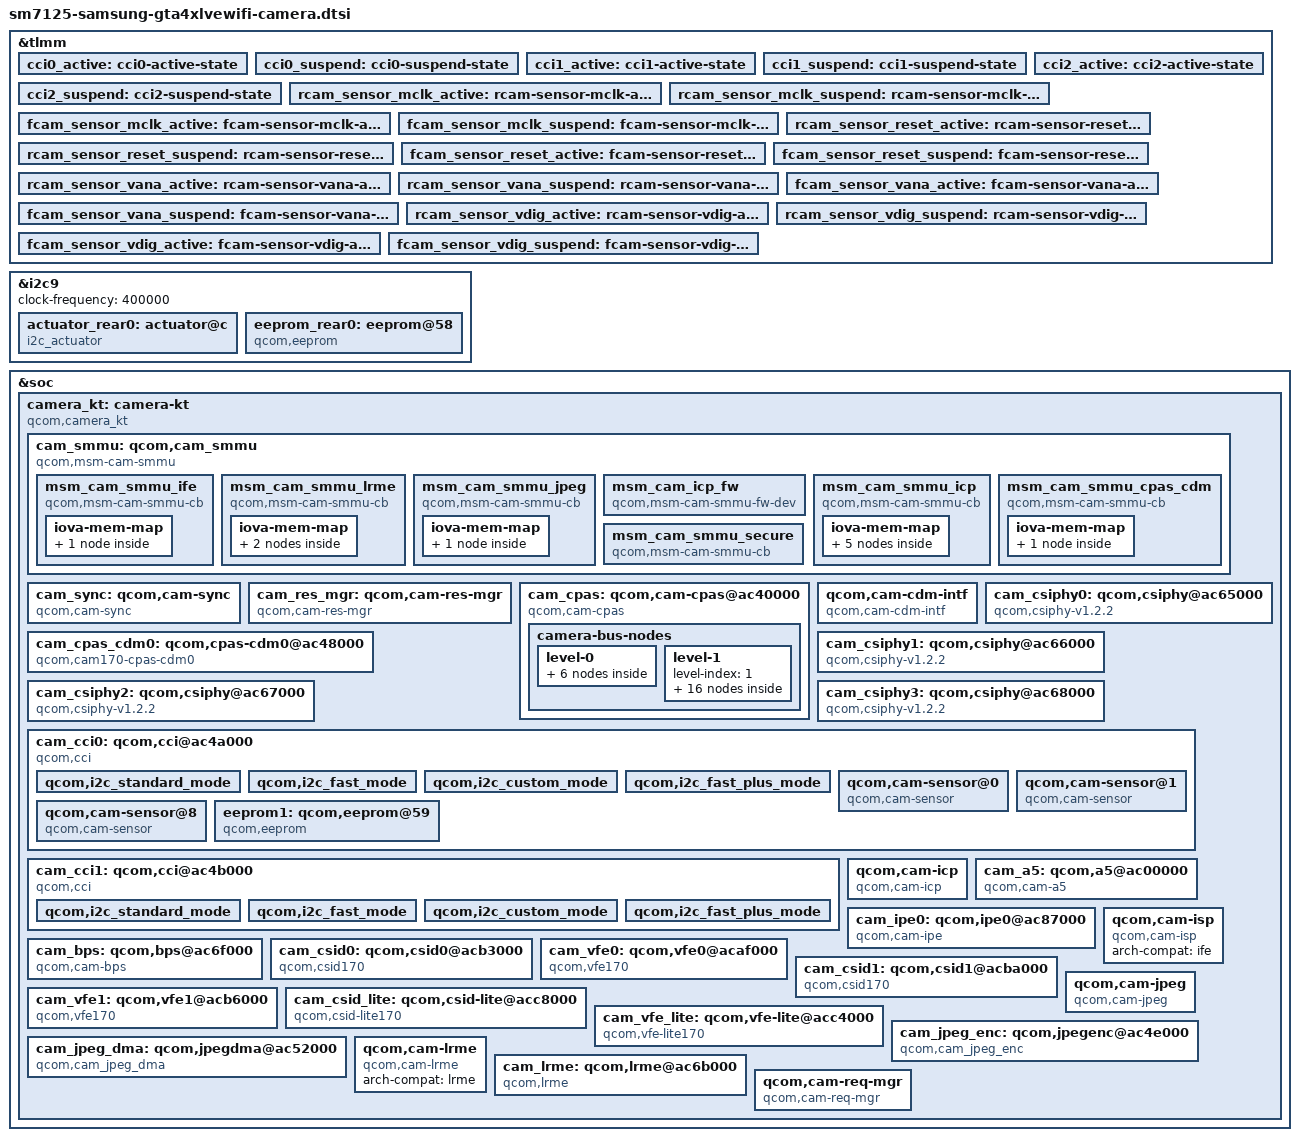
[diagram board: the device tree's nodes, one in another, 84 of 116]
// SPDX-License-Identifier: GPL-2.0
/*
 * Qualcomm Spectra CamX (camera_kt) Device Tree for
 * Samsung Galaxy Tab S6 Lite (2022) Wi-Fi (SM-P613 / gta4xlvewifi, SM7125 / atoll).
 *
 * Sensors:
 *   - Rear  (slot 0): Samsung S5K4HA (8MP, CCI0 Master 0, 0x5A, CSIPHY0)
 *                     + AF actuator (i2c9 @ 0x0C) + EEPROM (i2c9 @ 0x58)
 *   - Front (slot 1 & 8): GalaxyCore GC5035 (5MP, CCI0 Master 1, 0x6E, CSIPHY2)
 *                     + OTP EEPROM (CCI0 Master 1 @ 0x59)
 */

#include <dt-bindings/camera/msm-camera.h>
#include <dt-bindings/clock/qcom,camcc-sc7180.h>
#include <dt-bindings/clock/qcom,gcc-sc7180.h>
#include <dt-bindings/interconnect/qcom,sc7180.h>
#include <dt-bindings/interrupt-controller/arm-gic.h>

&tlmm {
	cci0_active: cci0-active-state {
		pins = "gpio17", "gpio18";
		function = "cci_i2c";
		drive-strength = <2>;
		bias-pull-up;
	};

	cci0_suspend: cci0-suspend-state {
		pins = "gpio17", "gpio18";
		function = "gpio";
		drive-strength = <2>;
		bias-pull-down;
	};

	cci1_active: cci1-active-state {
		pins = "gpio19", "gpio20";
		function = "cci_i2c";
		drive-strength = <2>;
		bias-pull-up;
	};

	cci1_suspend: cci1-suspend-state {
		pins = "gpio19", "gpio20";
		function = "gpio";
		drive-strength = <2>;
		bias-pull-down;
	};

	cci2_active: cci2-active-state {
		pins = "gpio27", "gpio28";
		function = "cci_i2c";
		drive-strength = <2>;
		bias-pull-up;
	};

	cci2_suspend: cci2-suspend-state {
		pins = "gpio27", "gpio28";
		function = "gpio";
		drive-strength = <2>;
		bias-pull-down;
	};

	rcam_sensor_mclk_active: rcam-sensor-mclk-active-state {
		pins = "gpio13";
		function = "cam_mclk";
		drive-strength = <4>;
		bias-disable;
	};

	rcam_sensor_mclk_suspend: rcam-sensor-mclk-suspend-state {
		pins = "gpio13";
		function = "cam_mclk";
		drive-strength = <4>;
		bias-pull-down;
		output-low;
	};

	fcam_sensor_mclk_active: fcam-sensor-mclk-active-state {
		pins = "gpio23";
		function = "cam_mclk";
		drive-strength = <4>;
		bias-disable;
	};

	fcam_sensor_mclk_suspend: fcam-sensor-mclk-suspend-state {
		pins = "gpio23";
		function = "cam_mclk";
		drive-strength = <4>;
		bias-pull-down;
		output-low;
	};

	rcam_sensor_reset_active: rcam-sensor-reset-active-state {
		pins = "gpio24";
		function = "gpio";
		drive-strength = <2>;
		bias-disable;
	};

	rcam_sensor_reset_suspend: rcam-sensor-reset-suspend-state {
		pins = "gpio24";
		function = "gpio";
		drive-strength = <2>;
		bias-pull-down;
	};

	fcam_sensor_reset_active: fcam-sensor-reset-active-state {
		pins = "gpio21";
		function = "gpio";
		drive-strength = <2>;
		bias-disable;
	};

	fcam_sensor_reset_suspend: fcam-sensor-reset-suspend-state {
		pins = "gpio21";
		function = "gpio";
		drive-strength = <2>;
		bias-pull-down;
	};

	rcam_sensor_vana_active: rcam-sensor-vana-active-state {
		pins = "gpio22";
		function = "gpio";
		drive-strength = <2>;
		bias-disable;
	};

	rcam_sensor_vana_suspend: rcam-sensor-vana-suspend-state {
		pins = "gpio22";
		function = "gpio";
		drive-strength = <2>;
		bias-pull-down;
	};

	fcam_sensor_vana_active: fcam-sensor-vana-active-state {
		pins = "gpio63";
		function = "gpio";
		drive-strength = <2>;
		bias-disable;
	};

	fcam_sensor_vana_suspend: fcam-sensor-vana-suspend-state {
		pins = "gpio63";
		function = "gpio";
		drive-strength = <2>;
		bias-pull-down;
	};

	rcam_sensor_vdig_active: rcam-sensor-vdig-active-state {
		pins = "gpio10";
		function = "gpio";
		drive-strength = <2>;
		bias-disable;
	};

	rcam_sensor_vdig_suspend: rcam-sensor-vdig-suspend-state {
		pins = "gpio10";
		function = "gpio";
		drive-strength = <2>;
		bias-pull-down;
	};

	fcam_sensor_vdig_active: fcam-sensor-vdig-active-state {
		pins = "gpio14";
		function = "gpio";
		drive-strength = <2>;
		bias-disable;
	};

	fcam_sensor_vdig_suspend: fcam-sensor-vdig-suspend-state {
		pins = "gpio14";
		function = "gpio";
		drive-strength = <2>;
		bias-pull-down;
	};
};

&i2c9 {
	clock-frequency = <400000>;
	status = "okay";

	actuator_rear0: actuator@c {
		cell-index = <0>;
		reg = <0x0c>;
		slave-addr = <0x18>;
		compatible = "i2c_actuator";

		rgltr-cntrl-support;
		cam_vaf-supply = <&vreg_l5a_2p7>;
		regulator-names = "cam_vaf";
		rgltr-min-voltage = <2800000>;
		rgltr-max-voltage = <2800000>;
		rgltr-load-current = <200000>;
	};

	eeprom_rear0: eeprom@58 {
		cell-index = <0>;
		reg = <0x58>;
		slave-addr = <0xb0>;
		compatible = "qcom,eeprom";
		i2c-freq-mode = <1>;
		sub-type = <2>;

		cam_vio-supply = <&vreg_l18a_3p0>;
		cam_vaf-supply = <&vreg_l5a_2p7>;
		regulator-names = "cam_vio", "cam_vaf", "cam_vana", "cam_vdig";
		rgltr-cntrl-support;
		rgltr-min-voltage = <1800000 2800000 0 0>;
		rgltr-max-voltage = <1800000 2800000 0 0>;
		rgltr-load-current = <200000 200000 0 0>;
		power-domains = <&camcc TITAN_TOP_GDSC>;

		gpio-no-mux = <0>;
		pinctrl-names = "cam_default", "cam_suspend";
		pinctrl-0 = <&rcam_sensor_mclk_active &rcam_sensor_reset_active
			     &rcam_sensor_vana_active &rcam_sensor_vdig_active>;
		pinctrl-1 = <&rcam_sensor_mclk_suspend &rcam_sensor_reset_suspend
			     &rcam_sensor_vana_suspend &rcam_sensor_vdig_suspend>;
		gpios = <&tlmm 13 0>,
			<&tlmm 24 0>,
			<&tlmm 22 0>,
			<&tlmm 10 0>;
		gpio-reset = <1>;
		gpio-vana = <2>;
		gpio-vdig = <3>;
		gpio-req-tbl-num = <0 1 2 3>;
		gpio-req-tbl-flags = <1 0 0 0>;
		gpio-req-tbl-label = "CAMIF_MCLK0", "CAM_RESET0",
				     "CAM_VANA", "CAM_VDIG";
	};
};

&soc {
	camera_kt: camera-kt {
		compatible = "qcom,camera_kt";
		#address-cells = <1>;
		#size-cells = <1>;
		ranges = <0 0 0 0xffffffff>;
		status = "okay";

		cam_smmu: qcom,cam_smmu {
			compatible = "qcom,msm-cam-smmu", "simple-bus";
			status = "okay";

			msm_cam_smmu_ife {
				compatible = "qcom,msm-cam-smmu-cb";
				iommus = <&apps_smmu 0x820 0x0>,
					 <&apps_smmu 0x840 0x0>,
					 <&apps_smmu 0x860 0x0>;
				cam-smmu-label = "ife";
				iova-mem-map {
					iova-mem-region-io {
						iova-region-name = "io";
						iova-region-start = <0x7400000>;
						iova-region-len = <0xd8c00000>;
						iova-region-id = <0x3>;
						status = "okay";
					};
				};
			};

			msm_cam_smmu_lrme {
				compatible = "qcom,msm-cam-smmu-cb";
				iommus = <&apps_smmu 0x0cc0 0x0>,
					 <&apps_smmu 0x0d40 0x0>;
				cam-smmu-label = "lrme";
				iova-mem-map {
					iova-mem-region-shared {
						iova-region-name = "shared";
						iova-region-start = <0x7400000>;
						iova-region-len = <0x6400000>;
						iova-region-id = <0x1>;
						status = "okay";
					};
					iova-mem-region-io {
						iova-region-name = "io";
						iova-region-start = <0xd800000>;
						iova-region-len = <0xd2800000>;
						iova-region-id = <0x3>;
						status = "okay";
					};
				};
			};

			msm_cam_smmu_jpeg {
				compatible = "qcom,msm-cam-smmu-cb";
				iommus = <&apps_smmu 0xd80 0x20>,
					 <&apps_smmu 0xda0 0x20>;
				cam-smmu-label = "jpeg";
				iova-mem-map {
					iova-mem-region-io {
						iova-region-name = "io";
						iova-region-start = <0x7400000>;
						iova-region-len = <0xd8c00000>;
						iova-region-id = <0x3>;
						status = "okay";
					};
				};
			};

			msm_cam_icp_fw {
				compatible = "qcom,msm-cam-smmu-fw-dev";
				cam-smmu-label = "icp";
				memory-region = <&camera_region>;
			};

			msm_cam_smmu_icp {
				compatible = "qcom,msm-cam-smmu-cb";
				iommus = <&apps_smmu 0x0ce2 0x0>,
					 <&apps_smmu 0x0c80 0x0>,
					 <&apps_smmu 0x0ca0 0x0>,
					 <&apps_smmu 0x0d00 0x0>,
					 <&apps_smmu 0x0d20 0x0>;
				cam-smmu-label = "icp";
				iova-mem-map {
					iova-mem-region-firmware {
						iova-region-name = "firmware";
						iova-region-start = <0x0>;
						iova-region-len = <0x500000>;
						iova-region-id = <0x0>;
						status = "okay";
					};

					iova-mem-region-shared {
						iova-region-name = "shared";
						iova-region-start = <0x7400000>;
						iova-region-len = <0x9600000>;
						iova-region-id = <0x1>;
						status = "okay";
					};

					iova-mem-region-secondary-heap {
						iova-region-name = "secheap";
						iova-region-start = <0x10a00000>;
						iova-region-len = <0x100000>;
						iova-region-id = <0x4>;
						status = "okay";
					};

					iova-mem-region-io {
						iova-region-name = "io";
						iova-region-start = <0x10c00000>;
						iova-region-len = <0xcf300000>;
						iova-region-id = <0x3>;
						status = "okay";
					};

					iova-mem-qdss-region {
						iova-region-name = "qdss";
						iova-region-start = <0x10b00000>;
						iova-region-len = <0x100000>;
						iova-region-id = <0x5>;
						qdss-phy-addr = <0x16790000>;
						status = "okay";
					};
				};
			};

			msm_cam_smmu_cpas_cdm {
				compatible = "qcom,msm-cam-smmu-cb";
				iommus = <&apps_smmu 0x0d60 0x0>,
					 <&apps_smmu 0x0d61 0x0>;
				cam-smmu-label = "cpas-cdm";
				iova-mem-map {
					iova-mem-region-io {
						iova-region-name = "io";
						iova-region-start = <0x7400000>;
						iova-region-len = <0xd8c00000>;
						iova-region-id = <0x3>;
						status = "okay";
					};
				};
			};

			msm_cam_smmu_secure {
				compatible = "qcom,msm-cam-smmu-cb";
				cam-smmu-label = "cam-secure";
				qcom,secure-cb;
			};
		};

		cam_sync: qcom,cam-sync {
			compatible = "qcom,cam-sync";
			status = "okay";
		};

		cam_res_mgr: qcom,cam-res-mgr {
			compatible = "qcom,cam-res-mgr";
			status = "okay";
		};

		cam_cpas: qcom,cam-cpas@ac40000 {
			cell-index = <0>;
			compatible = "qcom,cam-cpas";
			label = "cpas";
			arch-compat = "cpas_top";
			status = "okay";
			reg-names = "cam_cpas_top", "cam_camnoc";
			reg = <0x0ac40000 0x1000>,
			      <0x0ac42000 0x5000>;
			reg-cam-base = <0x40000 0x42000>;
			interrupt-names = "cpas_camnoc";
			interrupts = <GIC_SPI 459 IRQ_TYPE_EDGE_RISING>;
			qcom,cpas-hw-ver = <0x150110>;
			camnoc-axi-min-ib-bw = <3000000000>;
			power-domains = <&camcc TITAN_TOP_GDSC>;
			clock-names = "gcc_ahb_clk",
				      "gcc_axi_clk",
				      "soc_ahb_clk",
				      "slow_ahb_clk_src",
				      "cpas_ahb_clk",
				      "camnoc_axi_clk";
			clocks = <&gcc GCC_CAMERA_AHB_CLK>,
				 <&gcc GCC_CAMERA_HF_AXI_CLK>,
				 <&camcc CAM_CC_SOC_AHB_CLK>,
				 <&camcc CAM_CC_SLOW_AHB_CLK_SRC>,
				 <&camcc CAM_CC_CPAS_AHB_CLK>,
				 <&camcc CAM_CC_CAMNOC_AXI_CLK>;
			src-clock-name = "slow_ahb_clk_src";
			clock-rates = <0 0 0 0 0 0>,
				      <0 0 0 80000000 0 0>,
				      <0 0 0 80000000 0 0>,
				      <0 0 0 80000000 0 0>,
				      <0 0 0 80000000 0 0>,
				      <0 0 0 80000000 0 0>;
			clock-cntl-level = "suspend", "lowsvs", "svs",
					   "svs_l1", "nominal", "turbo";
			interconnects =
				<&gem_noc MASTER_APPSS_PROC 0 &config_noc SLAVE_CAMERA_CFG 0>,
				<&mmss_noc MASTER_CAMNOC_HF0 0 &mc_virt SLAVE_EBI1 0>,
				<&mmss_noc MASTER_CAMNOC_HF1 0 &mc_virt SLAVE_EBI1 0>,
				<&mmss_noc MASTER_CAMNOC_SF 0 &mc_virt SLAVE_EBI1 0>;
			interconnect-names = "cam_ahb",
					     "cam_hf_0_mnoc",
					     "cam_hf_1_mnoc",
					     "cam_sf_0_mnoc";
			cam-ahb-num-cases = <6>;
			cam-ahb-bw-KBps = <0 0>,
					  <0 89500>,
					  <0 125000>,
					  <0 125000>,
					  <0 250000>,
					  <0 250000>;
			client-id-based;
			camnoc-bus-width = <16>;
			camnoc-axi-clk-bw-margin-perc = <10>;
			client-names =
				"csiphy0", "csiphy1", "csiphy2", "csiphy3",
				"csid0", "csid1", "csid2", "cci0", "cci1",
				"ife0", "ife1", "ife2", "ipe0",
				"ipe1", "cam-cdm-intf0", "cpas-cdm0", "bps0",
				"icp0", "jpeg-dma0", "jpeg-enc0", "lrmecpas0";

			camera-bus-nodes {
				level-0 {
					level-index = <0>;
					camnoc-max-needed;

					cam_mnoc_hf0: mnoc-hf0 {
						cell-index = <0>;
						node-name = "cam_hf_0_mnoc";
						bus-width-factor = <1>;
						traffic-merge-type = <CAM_CPAS_TRAFFIC_MERGE_SUM>;
						ib-bw-voting-needed;
						qcom,axi-port-mnoc {
							interconnects = <&mmss_noc MASTER_CAMNOC_HF0 0 &mc_virt SLAVE_EBI1 0>;
							interconnect-names = "cam_hf_0_mnoc";
						};
					};

					cam_mnoc_hf1: mnoc-hf1 {
						cell-index = <1>;
						node-name = "cam_hf_1_mnoc";
						bus-width-factor = <1>;
						traffic-merge-type = <CAM_CPAS_TRAFFIC_MERGE_SUM>;
						ib-bw-voting-needed;
						qcom,axi-port-mnoc {
							interconnects = <&mmss_noc MASTER_CAMNOC_HF1 0 &mc_virt SLAVE_EBI1 0>;
							interconnect-names = "cam_hf_1_mnoc";
						};
					};

					cam_mnoc_sf0: mnoc-sf0 {
						cell-index = <2>;
						node-name = "cam_sf_0_mnoc";
						bus-width-factor = <1>;
						traffic-merge-type = <CAM_CPAS_TRAFFIC_MERGE_SUM>;
						ib-bw-voting-needed;
						qcom,axi-port-mnoc {
							interconnects = <&mmss_noc MASTER_CAMNOC_SF 0 &mc_virt SLAVE_EBI1 0>;
							interconnect-names = "cam_sf_0_mnoc";
						};
					};
				};

				level-1 {
					level-index = <1>;

					ife0-wr {
						cell-index = <3>;
						node-name = "ife0_wr";
						client-name = "ife0";
						traffic-data = <CAM_CPAS_PATH_DATA_ALL>;
						traffic-transaction-type = <CAM_CPAS_TRANSACTION_WRITE>;
						parent-node = <&cam_mnoc_hf0>;
					};

					ife1-wr {
						cell-index = <4>;
						node-name = "ife1_wr";
						client-name = "ife1";
						traffic-data = <CAM_CPAS_PATH_DATA_ALL>;
						traffic-transaction-type = <CAM_CPAS_TRANSACTION_WRITE>;
						parent-node = <&cam_mnoc_hf1>;
					};

					ife2-wr {
						cell-index = <5>;
						node-name = "ife2_wr";
						client-name = "ife2";
						traffic-data = <CAM_CPAS_PATH_DATA_ALL>;
						traffic-transaction-type = <CAM_CPAS_TRANSACTION_WRITE>;
						parent-node = <&cam_mnoc_hf1>;
					};

					ipe0-rd {
						cell-index = <6>;
						node-name = "ipe0_rd";
						client-name = "ipe0";
						traffic-data = <CAM_CPAS_PATH_DATA_ALL>;
						traffic-transaction-type = <CAM_CPAS_TRANSACTION_READ>;
						parent-node = <&cam_mnoc_sf0>;
					};

					ipe0-wr {
						cell-index = <7>;
						node-name = "ipe0_wr";
						client-name = "ipe0";
						traffic-data = <CAM_CPAS_PATH_DATA_ALL>;
						traffic-transaction-type = <CAM_CPAS_TRANSACTION_WRITE>;
						parent-node = <&cam_mnoc_sf0>;
					};

					bps0-rd {
						cell-index = <8>;
						node-name = "bps0_rd";
						client-name = "bps0";
						traffic-data = <CAM_CPAS_PATH_DATA_ALL>;
						traffic-transaction-type = <CAM_CPAS_TRANSACTION_READ>;
						parent-node = <&cam_mnoc_sf0>;
					};

					bps0-wr {
						cell-index = <9>;
						node-name = "bps0_wr";
						client-name = "bps0";
						traffic-data = <CAM_CPAS_PATH_DATA_ALL>;
						traffic-transaction-type = <CAM_CPAS_TRANSACTION_WRITE>;
						parent-node = <&cam_mnoc_sf0>;
					};

					icp0-rd {
						cell-index = <10>;
						node-name = "icp0_rd";
						client-name = "icp0";
						traffic-data = <CAM_CPAS_PATH_DATA_ALL>;
						traffic-transaction-type = <CAM_CPAS_TRANSACTION_READ>;
						parent-node = <&cam_mnoc_sf0>;
					};

					jpeg-enc0-wr {
						cell-index = <11>;
						node-name = "jpeg_enc0_wr";
						client-name = "jpeg-enc0";
						traffic-data = <CAM_CPAS_PATH_DATA_ALL>;
						traffic-transaction-type = <CAM_CPAS_TRANSACTION_WRITE>;
						parent-node = <&cam_mnoc_sf0>;
					};

					jpeg-dma0-wr {
						cell-index = <12>;
						node-name = "jpeg_dma0_wr";
						client-name = "jpeg-dma0";
						traffic-data = <CAM_CPAS_PATH_DATA_ALL>;
						traffic-transaction-type = <CAM_CPAS_TRANSACTION_WRITE>;
						parent-node = <&cam_mnoc_sf0>;
					};

					lrme0-rd {
						cell-index = <13>;
						node-name = "lrme0_rd";
						client-name = "lrmecpas0";
						traffic-data = <CAM_CPAS_PATH_DATA_ALL>;
						traffic-transaction-type = <CAM_CPAS_TRANSACTION_READ>;
						parent-node = <&cam_mnoc_sf0>;
					};

					cpas-cdm0-rd {
						cell-index = <14>;
						node-name = "cpas_cdm0_rd";
						client-name = "cpas-cdm0";
						traffic-data = <CAM_CPAS_PATH_DATA_ALL>;
						traffic-transaction-type = <CAM_CPAS_TRANSACTION_READ>;
						parent-node = <&cam_mnoc_sf0>;
					};

					lrme0-wr {
						cell-index = <15>;
						node-name = "lrme0_wr";
						client-name = "lrmecpas0";
						traffic-data = <CAM_CPAS_PATH_DATA_ALL>;
						traffic-transaction-type = <CAM_CPAS_TRANSACTION_WRITE>;
						parent-node = <&cam_mnoc_sf0>;
					};

					icp0-wr {
						cell-index = <16>;
						node-name = "icp0_wr";
						client-name = "icp0";
						traffic-data = <CAM_CPAS_PATH_DATA_ALL>;
						traffic-transaction-type = <CAM_CPAS_TRANSACTION_WRITE>;
						parent-node = <&cam_mnoc_sf0>;
					};

					jpeg-enc0-rd {
						cell-index = <17>;
						node-name = "jpeg_enc0_rd";
						client-name = "jpeg-enc0";
						traffic-data = <CAM_CPAS_PATH_DATA_ALL>;
						traffic-transaction-type = <CAM_CPAS_TRANSACTION_READ>;
						parent-node = <&cam_mnoc_sf0>;
					};

					jpeg-dma0-rd {
						cell-index = <18>;
						node-name = "jpeg_dma0_rd";
						client-name = "jpeg-dma0";
						traffic-data = <CAM_CPAS_PATH_DATA_ALL>;
						traffic-transaction-type = <CAM_CPAS_TRANSACTION_READ>;
						parent-node = <&cam_mnoc_sf0>;
					};
				};
			};
		};

		qcom,cam-cdm-intf {
			compatible = "qcom,cam-cdm-intf";
			cell-index = <0>;
			label = "cam-cdm-intf";
			num-hw-cdm = <1>;
			cdm-client-names = "vfe",
					   "jpegdma",
					   "jpegenc",
					   "lrmecdm";
			status = "okay";
		};

		cam_cpas_cdm0: qcom,cpas-cdm0@ac48000 {
			cell-index = <0>;
			compatible = "qcom,cam170-cpas-cdm0";
			label = "cpas-cdm";
			reg = <0x0ac48000 0x1000>;
			reg-names = "cpas-cdm";
			reg-cam-base = <0x48000>;
			interrupts = <GIC_SPI 469 IRQ_TYPE_EDGE_RISING>;
			interrupt-names = "cpas-cdm";
			power-domains = <&camcc TITAN_TOP_GDSC>;
			clock-names = "gcc_camera_ahb",
				      "gcc_camera_axi",
				      "cam_cc_soc_ahb_clk",
				      "cam_cc_cpas_ahb_clk",
				      "cam_cc_camnoc_axi_clk";
			clocks = <&gcc GCC_CAMERA_AHB_CLK>,
				 <&gcc GCC_CAMERA_HF_AXI_CLK>,
				 <&camcc CAM_CC_SOC_AHB_CLK>,
				 <&camcc CAM_CC_CPAS_AHB_CLK>,
				 <&camcc CAM_CC_CAMNOC_AXI_CLK>;
			clock-rates = <0 0 0 0 0>;
			clock-cntl-level = "svs";
			cdm-client-names = "ife", "ife3", "vfe", "jpegenc", "jpegdma", "lrmecdm";
			status = "okay";
		};

		cam_csiphy0: qcom,csiphy@ac65000 {
			cell-index = <0>;
			compatible = "qcom,csiphy-v1.2.2", "qcom,csiphy";
			reg = <0x0ac65000 0x1000>;
			reg-names = "csiphy";
			reg-cam-base = <0x65000>;
			interrupts = <GIC_SPI 477 IRQ_TYPE_EDGE_RISING>;
			interrupt-names = "csiphy";
			power-domains = <&camcc TITAN_TOP_GDSC>;
			regulator-names = "refgen", "mipi-csi-vdd1", "mipi-csi-vdd2";
			refgen-supply = <&refgen>;
			mipi-csi-vdd1-supply = <&vreg_l4a_0p9>;
			mipi-csi-vdd2-supply = <&vreg_l3c_1p2>;
			rgltr-cntrl-support;
			rgltr-min-voltage = <0 900000 1200000>;
			rgltr-max-voltage = <0 928000 1200000>;
			rgltr-load-current = <0 80000 80000>;
			clocks = <&camcc CAM_CC_CAMNOC_AXI_CLK>,
				 <&camcc CAM_CC_SOC_AHB_CLK>,
				 <&camcc CAM_CC_SLOW_AHB_CLK_SRC>,
				 <&camcc CAM_CC_CPAS_AHB_CLK>,
				 <&camcc CAM_CC_CPHY_RX_CLK_SRC>,
				 <&camcc CAM_CC_CSIPHY0_CLK>,
				 <&camcc CAM_CC_CSI0PHYTIMER_CLK_SRC>,
				 <&camcc CAM_CC_CSI0PHYTIMER_CLK>;
			clock-names = "camnoc_axi_clk",
				      "soc_ahb_clk",
				      "slow_ahb_src_clk",
				      "cpas_ahb_clk",
				      "cphy_rx_clk_src",
				      "csiphy0_clk",
				      "csi0phytimer_clk_src",
				      "csi0phytimer_clk";
			src-clock-name = "csi0phytimer_clk_src";
			clock-cntl-level = "svs", "svs_l1", "turbo";
			clock-rates = <0 0 0 0 270000000 0 300000000 0>,
				      <0 0 0 0 360000000 0 300000000 0>,
				      <0 0 0 0 360000000 0 300000000 0>;
			status = "okay";
		};

		cam_csiphy1: qcom,csiphy@ac66000 {
			cell-index = <1>;
			compatible = "qcom,csiphy-v1.2.2", "qcom,csiphy";
			reg = <0x0ac66000 0x1000>;
			reg-names = "csiphy";
			reg-cam-base = <0x66000>;
			interrupts = <GIC_SPI 478 IRQ_TYPE_EDGE_RISING>;
			interrupt-names = "csiphy";
			power-domains = <&camcc TITAN_TOP_GDSC>;
			regulator-names = "refgen", "mipi-csi-vdd1", "mipi-csi-vdd2";
			refgen-supply = <&refgen>;
			mipi-csi-vdd1-supply = <&vreg_l4a_0p9>;
			mipi-csi-vdd2-supply = <&vreg_l3c_1p2>;
			rgltr-cntrl-support;
			rgltr-min-voltage = <0 900000 1200000>;
			rgltr-max-voltage = <0 928000 1200000>;
			rgltr-load-current = <0 80000 80000>;
			clocks = <&camcc CAM_CC_CAMNOC_AXI_CLK>,
				 <&camcc CAM_CC_SOC_AHB_CLK>,
				 <&camcc CAM_CC_SLOW_AHB_CLK_SRC>,
				 <&camcc CAM_CC_CPAS_AHB_CLK>,
				 <&camcc CAM_CC_CPHY_RX_CLK_SRC>,
				 <&camcc CAM_CC_CSIPHY1_CLK>,
				 <&camcc CAM_CC_CSI1PHYTIMER_CLK_SRC>,
				 <&camcc CAM_CC_CSI1PHYTIMER_CLK>;
			clock-names = "camnoc_axi_clk",
				      "soc_ahb_clk",
				      "slow_ahb_src_clk",
				      "cpas_ahb_clk",
				      "cphy_rx_clk_src",
				      "csiphy1_clk",
				      "csi1phytimer_clk_src",
				      "csi1phytimer_clk";
			src-clock-name = "csi1phytimer_clk_src";
			clock-cntl-level = "svs", "svs_l1", "turbo";
			clock-rates = <0 0 0 0 270000000 0 300000000 0>,
				      <0 0 0 0 360000000 0 300000000 0>,
				      <0 0 0 0 360000000 0 300000000 0>;
			status = "okay";
		};

		cam_csiphy2: qcom,csiphy@ac67000 {
			cell-index = <2>;
			compatible = "qcom,csiphy-v1.2.2", "qcom,csiphy";
			reg = <0x0ac67000 0x1000>;
			reg-names = "csiphy";
			reg-cam-base = <0x67000>;
			interrupts = <GIC_SPI 479 IRQ_TYPE_EDGE_RISING>;
			interrupt-names = "csiphy";
			power-domains = <&camcc TITAN_TOP_GDSC>;
			regulator-names = "refgen", "mipi-csi-vdd1", "mipi-csi-vdd2";
			refgen-supply = <&refgen>;
			mipi-csi-vdd1-supply = <&vreg_l4a_0p9>;
			mipi-csi-vdd2-supply = <&vreg_l3c_1p2>;
			rgltr-cntrl-support;
			rgltr-min-voltage = <0 900000 1200000>;
			rgltr-max-voltage = <0 928000 1200000>;
			rgltr-load-current = <0 80000 80000>;
			clocks = <&camcc CAM_CC_CAMNOC_AXI_CLK>,
				 <&camcc CAM_CC_SOC_AHB_CLK>,
				 <&camcc CAM_CC_SLOW_AHB_CLK_SRC>,
				 <&camcc CAM_CC_CPAS_AHB_CLK>,
				 <&camcc CAM_CC_CPHY_RX_CLK_SRC>,
				 <&camcc CAM_CC_CSIPHY2_CLK>,
				 <&camcc CAM_CC_CSI2PHYTIMER_CLK_SRC>,
				 <&camcc CAM_CC_CSI2PHYTIMER_CLK>;
			clock-names = "camnoc_axi_clk",
				      "soc_ahb_clk",
				      "slow_ahb_src_clk",
				      "cpas_ahb_clk",
				      "cphy_rx_clk_src",
				      "csiphy2_clk",
				      "csi2phytimer_clk_src",
				      "csi2phytimer_clk";
			src-clock-name = "csi2phytimer_clk_src";
			clock-cntl-level = "svs", "svs_l1", "turbo";
			clock-rates = <0 0 0 0 300000000 0 300000000 0>,
				      <0 0 0 0 360000000 0 300000000 0>,
				      <0 0 0 0 360000000 0 300000000 0>;
			status = "okay";
		};

		cam_csiphy3: qcom,csiphy@ac68000 {
			cell-index = <3>;
			compatible = "qcom,csiphy-v1.2.2", "qcom,csiphy";
			reg = <0x0ac68000 0x1000>;
			reg-names = "csiphy";
			reg-cam-base = <0x68000>;
			interrupts = <GIC_SPI 461 IRQ_TYPE_EDGE_RISING>;
			interrupt-names = "csiphy";
			power-domains = <&camcc TITAN_TOP_GDSC>;
			regulator-names = "refgen", "mipi-csi-vdd1", "mipi-csi-vdd2";
			refgen-supply = <&refgen>;
			mipi-csi-vdd1-supply = <&vreg_l4a_0p9>;
			mipi-csi-vdd2-supply = <&vreg_l3c_1p2>;
			rgltr-cntrl-support;
			rgltr-min-voltage = <0 900000 1200000>;
			rgltr-max-voltage = <0 928000 1200000>;
			rgltr-load-current = <0 80000 80000>;
			clocks = <&camcc CAM_CC_CAMNOC_AXI_CLK>,
				 <&camcc CAM_CC_SOC_AHB_CLK>,
				 <&camcc CAM_CC_SLOW_AHB_CLK_SRC>,
				 <&camcc CAM_CC_CPAS_AHB_CLK>,
				 <&camcc CAM_CC_CPHY_RX_CLK_SRC>,
				 <&camcc CAM_CC_CSIPHY3_CLK>,
				 <&camcc CAM_CC_CSI3PHYTIMER_CLK_SRC>,
				 <&camcc CAM_CC_CSI3PHYTIMER_CLK>;
			clock-names = "camnoc_axi_clk",
				      "soc_ahb_clk",
				      "slow_ahb_src_clk",
				      "cpas_ahb_clk",
				      "cphy_rx_clk_src",
				      "csiphy3_clk",
				      "csi3phytimer_clk_src",
				      "csi3phytimer_clk";
			src-clock-name = "csi3phytimer_clk_src";
			clock-cntl-level = "svs", "svs_l1", "turbo";
			clock-rates = <0 0 0 0 270000000 0 300000000 0>,
				      <0 0 0 0 360000000 0 300000000 0>,
				      <0 0 0 0 360000000 0 300000000 0>;
			status = "okay";
		};

		cam_cci0: qcom,cci@ac4a000 {
			cell-index = <0>;
			compatible = "qcom,cci", "simple-bus";
			#address-cells = <1>;
			#size-cells = <0>;
			reg = <0x0ac4a000 0x1000>;
			reg-names = "cci";
			reg-cam-base = <0x4a000>;
			interrupt-names = "cci";
			interrupts = <GIC_SPI 468 IRQ_TYPE_EDGE_RISING>;
			status = "okay";
			power-domains = <&camcc TITAN_TOP_GDSC>;
			clocks = <&camcc CAM_CC_CAMNOC_AXI_CLK>,
				 <&camcc CAM_CC_SOC_AHB_CLK>,
				 <&camcc CAM_CC_SLOW_AHB_CLK_SRC>,
				 <&camcc CAM_CC_CPAS_AHB_CLK>,
				 <&camcc CAM_CC_CCI_0_CLK>,
				 <&camcc CAM_CC_CCI_0_CLK_SRC>;
			clock-names = "camnoc_axi_clk",
				      "soc_ahb_clk",
				      "slow_ahb_src_clk",
				      "cpas_ahb_clk",
				      "cci_clk",
				      "cci_clk_src";
			src-clock-name = "cci_clk_src";
			clock-cntl-level = "lowsvs";
			clock-rates = <0 0 0 0 0 37500000>;
			pinctrl-names = "cam_default", "cam_suspend";
			pinctrl-0 = <&cci0_active &cci1_active>;
			pinctrl-1 = <&cci0_suspend &cci1_suspend>;
			gpios = <&tlmm 17 0>,
				<&tlmm 18 0>,
				<&tlmm 19 0>,
				<&tlmm 20 0>;
			gpio-req-tbl-num = <0 1 2 3>;
			gpio-req-tbl-flags = <1 1 1 1>;
			gpio-req-tbl-label = "CCI_I2C_DATA0",
					     "CCI_I2C_CLK0",
					     "CCI_I2C_DATA1",
					     "CCI_I2C_CLK1";

			qcom,i2c_standard_mode {
				hw-thigh = <201>;
				hw-tlow = <174>;
				hw-tsu-sto = <204>;
				hw-tsu-sta = <231>;
				hw-thd-dat = <22>;
				hw-thd-sta = <162>;
				hw-tbuf = <227>;
				hw-scl-stretch-en = <0>;
				hw-trdhld = <6>;
				hw-tsp = <3>;
				cci-clk-src = <37500000>;
				status = "okay";
			};

			qcom,i2c_fast_mode {
				hw-thigh = <38>;
				hw-tlow = <56>;
				hw-tsu-sto = <40>;
				hw-tsu-sta = <40>;
				hw-thd-dat = <22>;
				hw-thd-sta = <35>;
				hw-tbuf = <62>;
				hw-scl-stretch-en = <0>;
				hw-trdhld = <6>;
				hw-tsp = <3>;
				cci-clk-src = <37500000>;
				status = "okay";
			};

			qcom,i2c_custom_mode {
				hw-thigh = <38>;
				hw-tlow = <56>;
				hw-tsu-sto = <40>;
				hw-tsu-sta = <40>;
				hw-thd-dat = <22>;
				hw-thd-sta = <35>;
				hw-tbuf = <62>;
				hw-scl-stretch-en = <1>;
				hw-trdhld = <6>;
				hw-tsp = <3>;
				cci-clk-src = <37500000>;
				status = "okay";
			};

			qcom,i2c_fast_plus_mode {
				hw-thigh = <16>;
				hw-tlow = <22>;
				hw-tsu-sto = <17>;
				hw-tsu-sta = <18>;
				hw-thd-dat = <16>;
				hw-thd-sta = <15>;
				hw-tbuf = <24>;
				hw-scl-stretch-en = <0>;
				hw-trdhld = <3>;
				hw-tsp = <3>;
				cci-clk-src = <37500000>;
				status = "okay";
			};

			/* Rear CAM - 8MP Wide, S5K4HA */
			qcom,cam-sensor@0 {
				cell-index = <0>;
				compatible = "qcom,cam-sensor";
				reg = <0x0>;
				slave-addr = <0x5a>;
				csiphy-sd-index = <0>;
				sensor-position-roll = <90>;
				sensor-position-pitch = <0>;
				sensor-position-yaw = <180>;

				actuator-src = <&actuator_rear0>;
				eeprom-src = <&eeprom_rear0>;

				cam_vio-supply = <&vreg_l18a_3p0>;
				cam_vaf-supply = <&vreg_l5a_2p7>;
				regulator-names = "cam_vio", "cam_vaf", "cam_vana", "cam_vdig";
				rgltr-cntrl-support;
				rgltr-min-voltage = <1800000 2800000 0 0>;
				rgltr-max-voltage = <1800000 2800000 0 0>;
				rgltr-load-current = <200000 200000 0 0>;
				power-domains = <&camcc TITAN_TOP_GDSC>;

				gpio-no-mux = <0>;
				pinctrl-names = "cam_default", "cam_suspend";
				pinctrl-0 = <&rcam_sensor_mclk_active &rcam_sensor_reset_active
					     &rcam_sensor_vana_active &rcam_sensor_vdig_active>;
				pinctrl-1 = <&rcam_sensor_mclk_suspend &rcam_sensor_reset_suspend
					     &rcam_sensor_vana_suspend &rcam_sensor_vdig_suspend>;
				gpios = <&tlmm 13 0>,
					<&tlmm 24 0>,
					<&tlmm 22 0>,
					<&tlmm 10 0>;
				gpio-reset = <1>;
				gpio-vana = <2>;
				gpio-vdig = <3>;
				gpio-req-tbl-num = <0 1 2 3>;
				gpio-req-tbl-flags = <1 0 0 0>;
				gpio-req-tbl-label = "CAMIF_MCLK0", "CAM_RESET0",
						     "CAM_VANA", "CAM_VDIG";

				sensor-mode = <0>;
				cci-device = <0>;
				cci-master = <0>;
				status = "okay";
				clocks = <&camcc CAM_CC_MCLK0_CLK>;
				clock-names = "cam_clk";
				clock-cntl-level = "turbo";
				clock-rates = <24000000>;
			};

			/* Front CAM - 5MP Wide, GC5035 */
			qcom,cam-sensor@1 {
				cell-index = <1>;
				compatible = "qcom,cam-sensor";
				reg = <0x1>;
				slave-addr = <0x6e>;
				csiphy-sd-index = <2>;
				sensor-position-roll = <270>;
				sensor-position-pitch = <0>;
				sensor-position-yaw = <0>;

				eeprom-src = <&eeprom1>;

				cam_vio-supply = <&vreg_l18a_3p0>;
				regulator-names = "cam_vio", "cam_vana", "cam_vdig";
				rgltr-cntrl-support;
				rgltr-min-voltage = <1800000 0 0>;
				rgltr-max-voltage = <1800000 0 0>;
				rgltr-load-current = <200000 0 0>;
				power-domains = <&camcc TITAN_TOP_GDSC>;

				gpio-no-mux = <0>;
				pinctrl-names = "cam_default", "cam_suspend";
				pinctrl-0 = <&fcam_sensor_mclk_active &fcam_sensor_reset_active
					     &fcam_sensor_vana_active &fcam_sensor_vdig_active>;
				pinctrl-1 = <&fcam_sensor_mclk_suspend &fcam_sensor_reset_suspend
					     &fcam_sensor_vana_suspend &fcam_sensor_vdig_suspend>;
				gpios = <&tlmm 23 0>,
					<&tlmm 21 0>,
					<&tlmm 63 0>,
					<&tlmm 14 0>;
				gpio-reset = <1>;
				gpio-vana = <2>;
				gpio-vdig = <3>;
				gpio-req-tbl-num = <0 1 2 3>;
				gpio-req-tbl-flags = <1 0 0 0>;
				gpio-req-tbl-label = "CAMIF_MCLK4", "CAM_RESET1",
						     "CAM_VANA", "CAM_VDIG";

				sensor-mode = <0>;
				cci-device = <0>;
				cci-master = <1>;
				status = "okay";
				clocks = <&camcc CAM_CC_MCLK4_CLK>;
				clock-names = "cam_clk";
				clock-cntl-level = "turbo";
				clock-rates = <24000000>;
			};

			/* Front full CAM - 5MP Wide, GC5035 */
			qcom,cam-sensor@8 {
				cell-index = <8>;
				compatible = "qcom,cam-sensor";
				reg = <0x8>;
				slave-addr = <0x6e>;
				csiphy-sd-index = <2>;
				sensor-position-roll = <270>;
				sensor-position-pitch = <0>;
				sensor-position-yaw = <0>;

				eeprom-src = <&eeprom1>;

				cam_vio-supply = <&vreg_l18a_3p0>;
				regulator-names = "cam_vio", "cam_vana", "cam_vdig";
				rgltr-cntrl-support;
				rgltr-min-voltage = <1800000 0 0>;
				rgltr-max-voltage = <1800000 0 0>;
				rgltr-load-current = <200000 0 0>;
				power-domains = <&camcc TITAN_TOP_GDSC>;

				gpio-no-mux = <0>;
				pinctrl-names = "cam_default", "cam_suspend";
				pinctrl-0 = <&fcam_sensor_mclk_active &fcam_sensor_reset_active
					     &fcam_sensor_vana_active &fcam_sensor_vdig_active>;
				pinctrl-1 = <&fcam_sensor_mclk_suspend &fcam_sensor_reset_suspend
					     &fcam_sensor_vana_suspend &fcam_sensor_vdig_suspend>;
				gpios = <&tlmm 23 0>,
					<&tlmm 21 0>,
					<&tlmm 63 0>,
					<&tlmm 14 0>;
				gpio-reset = <1>;
				gpio-vana = <2>;
				gpio-vdig = <3>;
				gpio-req-tbl-num = <0 1 2 3>;
				gpio-req-tbl-flags = <1 0 0 0>;
				gpio-req-tbl-label = "CAMIF_MCLK4", "CAM_RESET1",
						     "CAM_VANA", "CAM_VDIG";

				sensor-mode = <0>;
				cci-device = <0>;
				cci-master = <1>;
				status = "okay";
				clocks = <&camcc CAM_CC_MCLK4_CLK>;
				clock-names = "cam_clk";
				clock-cntl-level = "turbo";
				clock-rates = <24000000>;
			};

			eeprom1: qcom,eeprom@59 {
				cell-index = <1>;
				compatible = "qcom,eeprom";
				reg = <0x59>;
				slave-addr = <0x6e>;
				i2c-freq-mode = <1>;
				sub-type = <2>;

				cam_vio-supply = <&vreg_l18a_3p0>;
				regulator-names = "cam_vio", "cam_vana", "cam_vdig";
				rgltr-cntrl-support;
				rgltr-min-voltage = <1800000 0 0>;
				rgltr-max-voltage = <1800000 0 0>;
				rgltr-load-current = <200000 0 0>;
				power-domains = <&camcc TITAN_TOP_GDSC>;

				gpio-no-mux = <0>;
				pinctrl-names = "cam_default", "cam_suspend";
				pinctrl-0 = <&fcam_sensor_mclk_active &fcam_sensor_reset_active
					     &fcam_sensor_vana_active &fcam_sensor_vdig_active>;
				pinctrl-1 = <&fcam_sensor_mclk_suspend &fcam_sensor_reset_suspend
					     &fcam_sensor_vana_suspend &fcam_sensor_vdig_suspend>;
				gpios = <&tlmm 23 0>,
					<&tlmm 21 0>,
					<&tlmm 63 0>,
					<&tlmm 14 0>;
				gpio-reset = <1>;
				gpio-vana = <2>;
				gpio-vdig = <3>;
				gpio-req-tbl-num = <0 1 2 3>;
				gpio-req-tbl-flags = <1 0 0 0>;
				gpio-req-tbl-label = "CAMIF_MCLK4", "CAM_RESET1",
						     "CAM_VANA", "CAM_VDIG";

				sensor-mode = <0>;
				cci-device = <0>;
				cci-master = <1>;
				status = "okay";
				clocks = <&camcc CAM_CC_MCLK4_CLK>;
				clock-names = "cam_clk";
				clock-cntl-level = "turbo";
				clock-rates = <24000000>;
			};
		};

		cam_cci1: qcom,cci@ac4b000 {
			cell-index = <1>;
			compatible = "qcom,cci";
			#address-cells = <1>;
			#size-cells = <0>;
			reg = <0x0ac4b000 0x1000>;
			reg-names = "cci";
			reg-cam-base = <0x4b000>;
			interrupt-names = "cci";
			interrupts = <GIC_SPI 462 IRQ_TYPE_EDGE_RISING>;
			status = "okay";
			power-domains = <&camcc TITAN_TOP_GDSC>;
			clocks = <&camcc CAM_CC_CAMNOC_AXI_CLK>,
				 <&camcc CAM_CC_SOC_AHB_CLK>,
				 <&camcc CAM_CC_SLOW_AHB_CLK_SRC>,
				 <&camcc CAM_CC_CPAS_AHB_CLK>,
				 <&camcc CAM_CC_CCI_1_CLK>,
				 <&camcc CAM_CC_CCI_1_CLK_SRC>;
			clock-names = "camnoc_axi_clk",
				      "soc_ahb_clk",
				      "slow_ahb_src_clk",
				      "cpas_ahb_clk",
				      "cci_clk",
				      "cci_clk_src";
			src-clock-name = "cci_clk_src";
			clock-cntl-level = "lowsvs";
			clock-rates = <0 0 0 0 0 37500000>;
			pinctrl-names = "cam_default", "cam_suspend";
			pinctrl-0 = <&cci2_active>;
			pinctrl-1 = <&cci2_suspend>;
			gpios = <&tlmm 27 0>,
				<&tlmm 28 0>;
			gpio-req-tbl-num = <0 1>;
			gpio-req-tbl-flags = <1 1>;
			gpio-req-tbl-label = "CCI_I2C_DATA2",
					     "CCI_I2C_CLK2";

			qcom,i2c_standard_mode {
				hw-thigh = <201>;
				hw-tlow = <174>;
				hw-tsu-sto = <204>;
				hw-tsu-sta = <231>;
				hw-thd-dat = <22>;
				hw-thd-sta = <162>;
				hw-tbuf = <227>;
				hw-scl-stretch-en = <0>;
				hw-trdhld = <6>;
				hw-tsp = <3>;
				cci-clk-src = <37500000>;
				status = "okay";
			};

			qcom,i2c_fast_mode {
				hw-thigh = <38>;
				hw-tlow = <56>;
				hw-tsu-sto = <40>;
				hw-tsu-sta = <40>;
				hw-thd-dat = <22>;
				hw-thd-sta = <35>;
				hw-tbuf = <62>;
				hw-scl-stretch-en = <0>;
				hw-trdhld = <6>;
				hw-tsp = <3>;
				cci-clk-src = <37500000>;
				status = "okay";
			};

			qcom,i2c_custom_mode {
				hw-thigh = <38>;
				hw-tlow = <56>;
				hw-tsu-sto = <40>;
				hw-tsu-sta = <40>;
				hw-thd-dat = <22>;
				hw-thd-sta = <35>;
				hw-tbuf = <62>;
				hw-scl-stretch-en = <1>;
				hw-trdhld = <6>;
				hw-tsp = <3>;
				cci-clk-src = <37500000>;
				status = "okay";
			};

			qcom,i2c_fast_plus_mode {
				hw-thigh = <16>;
				hw-tlow = <22>;
				hw-tsu-sto = <17>;
				hw-tsu-sta = <18>;
				hw-thd-dat = <16>;
				hw-thd-sta = <15>;
				hw-tbuf = <24>;
				hw-scl-stretch-en = <0>;
				hw-trdhld = <3>;
				hw-tsp = <3>;
				cci-clk-src = <37500000>;
				status = "okay";
			};
		};

		qcom,cam-icp {
			compatible = "qcom,cam-icp";
			compat-hw-name = "qcom,a5",
					 "qcom,ipe0",
					 "qcom,bps";
			num-a5 = <1>;
			num-ipe = <1>;
			num-bps = <1>;
			icp_pc_en;
			status = "okay";
		};

		cam_a5: qcom,a5@ac00000 {
			cell-index = <0>;
			compatible = "qcom,cam-a5";
			reg = <0x0ac00000 0x6000>,
			      <0x0ac10000 0x8000>,
			      <0x0ac18000 0x3000>;
			reg-names = "a5_qgic", "a5_sierra", "a5_csr";
			reg-cam-base = <0x00000 0x10000 0x18000>;
			interrupts = <GIC_SPI 463 IRQ_TYPE_EDGE_RISING>;
			interrupt-names = "a5";
			power-domains = <&camcc TITAN_TOP_GDSC>;
			clock-names = "gcc_cam_ahb_clk",
				      "gcc_cam_axi_clk",
				      "soc_fast_ahb",
				      "soc_ahb_clk",
				      "cpas_ahb_clk",
				      "camnoc_axi_clk",
				      "icp_clk",
				      "icp_clk_src";
			clocks = <&gcc GCC_CAMERA_AHB_CLK>,
				 <&gcc GCC_CAMERA_HF_AXI_CLK>,
				 <&camcc CAM_CC_FAST_AHB_CLK_SRC>,
				 <&camcc CAM_CC_SOC_AHB_CLK>,
				 <&camcc CAM_CC_CPAS_AHB_CLK>,
				 <&camcc CAM_CC_CAMNOC_AXI_CLK>,
				 <&camcc CAM_CC_ICP_CLK>,
				 <&camcc CAM_CC_ICP_CLK_SRC>;
			clock-rates = <0 0 200000000 0 0 0 0 360000000>,
				      <0 0 200000000 0 0 0 0 600000000>;
			clock-cntl-level = "svs", "turbo";
			fw_name = "CAMERA_ICP.elf";
			ubwc-cfg = <0x73 0x1cf>;
			status = "okay";
		};

		cam_ipe0: qcom,ipe0@ac87000 {
			cell-index = <0>;
			compatible = "qcom,cam-ipe";
			reg = <0x0ac87000 0x3000>;
			reg-names = "ipe0_top";
			reg-cam-base = <0x87000>;
			power-domains = <&camcc IPE_0_GDSC>;
			clock-names = "ipe_0_ahb_clk",
				      "ipe_0_areg_clk",
				      "ipe_0_axi_clk",
				      "ipe_0_clk",
				      "ipe_0_clk_src";
			src-clock-name = "ipe_0_clk_src";
			clocks = <&camcc CAM_CC_IPE_0_AHB_CLK>,
				 <&camcc CAM_CC_IPE_0_AREG_CLK>,
				 <&camcc CAM_CC_IPE_0_AXI_CLK>,
				 <&camcc CAM_CC_IPE_0_CLK>,
				 <&camcc CAM_CC_IPE_0_CLK_SRC>;
			clock-rates = <0 0 0 0 360000000>,
				      <0 0 0 0 432000000>,
				      <0 0 0 0 540000000>,
				      <0 0 0 0 600000000>;
			clock-cntl-level = "svs", "svs_l1", "nominal", "turbo";
			status = "okay";
		};

		cam_bps: qcom,bps@ac6f000 {
			cell-index = <0>;
			compatible = "qcom,cam-bps";
			reg = <0x0ac6f000 0x3000>;
			reg-names = "bps_top";
			reg-cam-base = <0x6f000>;
			power-domains = <&camcc BPS_GDSC>;
			clock-names = "bps_ahb_clk",
				      "bps_areg_clk",
				      "bps_axi_clk",
				      "bps_clk",
				      "bps_clk_src";
			src-clock-name = "bps_clk_src";
			clocks = <&camcc CAM_CC_BPS_AHB_CLK>,
				 <&camcc CAM_CC_BPS_AREG_CLK>,
				 <&camcc CAM_CC_BPS_AXI_CLK>,
				 <&camcc CAM_CC_BPS_CLK>,
				 <&camcc CAM_CC_BPS_CLK_SRC>;
			clock-rates = <0 0 0 0 360000000>,
				      <0 0 0 0 432000000>,
				      <0 0 0 0 480000000>,
				      <0 0 0 0 600000000>;
			clock-cntl-level = "svs", "svs_l1", "nominal", "turbo";
			status = "okay";
		};

		qcom,cam-isp {
			compatible = "qcom,cam-isp";
			arch-compat = "ife";
			status = "okay";
		};

		cam_csid0: qcom,csid0@acb3000 {
			cell-index = <0>;
			compatible = "qcom,csid170";
			reg-names = "csid";
			reg = <0x0acb3000 0x1000>;
			reg-cam-base = <0xb3000>;
			interrupt-names = "csid";
			interrupts = <GIC_SPI 464 IRQ_TYPE_EDGE_RISING>;
			power-domains = <&camcc TITAN_TOP_GDSC>,
					<&camcc IFE_0_GDSC>;
			clock-names = "camera_ahb",
				      "camera_axi",
				      "soc_ahb_clk",
				      "cpas_ahb_clk",
				      "slow_ahb_clk_src",
				      "ife_csid_clk",
				      "ife_csid_clk_src",
				      "ife_cphy_rx_clk",
				      "cphy_rx_clk_src",
				      "ife_clk",
				      "ife_clk_src",
				      "camnoc_axi_clk",
				      "ife_axi_clk";
			clocks = <&gcc GCC_CAMERA_AHB_CLK>,
				 <&gcc GCC_CAMERA_HF_AXI_CLK>,
				 <&camcc CAM_CC_SOC_AHB_CLK>,
				 <&camcc CAM_CC_CPAS_AHB_CLK>,
				 <&camcc CAM_CC_SLOW_AHB_CLK_SRC>,
				 <&camcc CAM_CC_IFE_0_CSID_CLK>,
				 <&camcc CAM_CC_IFE_0_CSID_CLK_SRC>,
				 <&camcc CAM_CC_IFE_0_CPHY_RX_CLK>,
				 <&camcc CAM_CC_CPHY_RX_CLK_SRC>,
				 <&camcc CAM_CC_IFE_0_CLK>,
				 <&camcc CAM_CC_IFE_0_CLK_SRC>,
				 <&camcc CAM_CC_CAMNOC_AXI_CLK>,
				 <&camcc CAM_CC_IFE_0_AXI_CLK>;
			clock-rates = <0 0 0 0 0 0 270000000 0 0 0 360000000 0 0>,
				      <0 0 0 0 0 0 360000000 0 0 0 432000000 0 0>,
				      <0 0 0 0 0 0 480000000 0 0 0 600000000 0 0>;
			clock-cntl-level = "svs", "svs_l1", "turbo";
			src-clock-name = "ife_csid_clk_src";
			status = "okay";
		};

		cam_vfe0: qcom,vfe0@acaf000 {
			cell-index = <0>;
			compatible = "qcom,vfe170";
			reg-names = "ife", "cam_camnoc";
			reg = <0x0acaf000 0x4000>,
			      <0x0ac42000 0x5000>;
			reg-cam-base = <0xaf000 0x42000>;
			interrupt-names = "ife";
			interrupts = <GIC_SPI 465 IRQ_TYPE_EDGE_RISING>;
			power-domains = <&camcc TITAN_TOP_GDSC>,
					<&camcc IFE_0_GDSC>;
			clock-names = "camera_ahb",
				      "camera_axi",
				      "soc_ahb_clk",
				      "cpas_ahb_clk",
				      "slow_ahb_clk_src",
				      "ife_clk",
				      "ife_clk_src",
				      "camnoc_axi_clk",
				      "ife_axi_clk";
			clocks = <&gcc GCC_CAMERA_AHB_CLK>,
				 <&gcc GCC_CAMERA_HF_AXI_CLK>,
				 <&camcc CAM_CC_SOC_AHB_CLK>,
				 <&camcc CAM_CC_CPAS_AHB_CLK>,
				 <&camcc CAM_CC_SLOW_AHB_CLK_SRC>,
				 <&camcc CAM_CC_IFE_0_CLK>,
				 <&camcc CAM_CC_IFE_0_CLK_SRC>,
				 <&camcc CAM_CC_CAMNOC_AXI_CLK>,
				 <&camcc CAM_CC_IFE_0_AXI_CLK>;
			clock-rates = <0 0 0 0 0 0 360000000 0 0>,
				      <0 0 0 0 0 0 432000000 0 0>,
				      <0 0 0 0 0 0 600000000 0 0>;
			clock-cntl-level = "svs", "svs_l1", "turbo";
			src-clock-name = "ife_clk_src";
			clock-names-option = "ife_dsp_clk";
			clocks-option = <&camcc CAM_CC_IFE_0_DSP_CLK>;
			clock-rates-option = <600000000>;
			status = "okay";
		};

		cam_csid1: qcom,csid1@acba000 {
			cell-index = <1>;
			compatible = "qcom,csid170";
			reg-names = "csid";
			reg = <0x0acba000 0x1000>;
			reg-cam-base = <0xba000>;
			interrupt-names = "csid";
			interrupts = <GIC_SPI 466 IRQ_TYPE_EDGE_RISING>;
			power-domains = <&camcc TITAN_TOP_GDSC>,
					<&camcc IFE_1_GDSC>;
			clock-names = "camera_ahb",
				      "camera_axi",
				      "soc_ahb_clk",
				      "cpas_ahb_clk",
				      "slow_ahb_clk_src",
				      "ife_csid_clk",
				      "ife_csid_clk_src",
				      "ife_cphy_rx_clk",
				      "cphy_rx_clk_src",
				      "ife_clk",
				      "ife_clk_src",
				      "camnoc_axi_clk",
				      "ife_axi_clk";
			clocks = <&gcc GCC_CAMERA_AHB_CLK>,
				 <&gcc GCC_CAMERA_HF_AXI_CLK>,
				 <&camcc CAM_CC_SOC_AHB_CLK>,
				 <&camcc CAM_CC_CPAS_AHB_CLK>,
				 <&camcc CAM_CC_SLOW_AHB_CLK_SRC>,
				 <&camcc CAM_CC_IFE_1_CSID_CLK>,
				 <&camcc CAM_CC_IFE_1_CSID_CLK_SRC>,
				 <&camcc CAM_CC_IFE_1_CPHY_RX_CLK>,
				 <&camcc CAM_CC_CPHY_RX_CLK_SRC>,
				 <&camcc CAM_CC_IFE_1_CLK>,
				 <&camcc CAM_CC_IFE_1_CLK_SRC>,
				 <&camcc CAM_CC_CAMNOC_AXI_CLK>,
				 <&camcc CAM_CC_IFE_1_AXI_CLK>;
			clock-rates = <0 0 0 0 0 0 270000000 0 0 0 360000000 0 0>,
				      <0 0 0 0 0 0 360000000 0 0 0 432000000 0 0>,
				      <0 0 0 0 0 0 480000000 0 0 0 600000000 0 0>;
			clock-cntl-level = "svs", "svs_l1", "turbo";
			src-clock-name = "ife_csid_clk_src";
			status = "okay";
		};

		cam_vfe1: qcom,vfe1@acb6000 {
			cell-index = <1>;
			compatible = "qcom,vfe170";
			reg-names = "ife", "cam_camnoc";
			reg = <0x0acb6000 0x4000>,
			      <0x0ac42000 0x5000>;
			reg-cam-base = <0xb6000 0x42000>;
			interrupt-names = "ife";
			interrupts = <GIC_SPI 467 IRQ_TYPE_EDGE_RISING>;
			power-domains = <&camcc TITAN_TOP_GDSC>,
					<&camcc IFE_1_GDSC>;
			clock-names = "camera_ahb",
				      "camera_axi",
				      "soc_ahb_clk",
				      "cpas_ahb_clk",
				      "slow_ahb_clk_src",
				      "ife_clk",
				      "ife_clk_src",
				      "camnoc_axi_clk",
				      "ife_axi_clk";
			clocks = <&gcc GCC_CAMERA_AHB_CLK>,
				 <&gcc GCC_CAMERA_HF_AXI_CLK>,
				 <&camcc CAM_CC_SOC_AHB_CLK>,
				 <&camcc CAM_CC_CPAS_AHB_CLK>,
				 <&camcc CAM_CC_SLOW_AHB_CLK_SRC>,
				 <&camcc CAM_CC_IFE_1_CLK>,
				 <&camcc CAM_CC_IFE_1_CLK_SRC>,
				 <&camcc CAM_CC_CAMNOC_AXI_CLK>,
				 <&camcc CAM_CC_IFE_1_AXI_CLK>;
			clock-rates = <0 0 0 0 0 0 360000000 0 0>,
				      <0 0 0 0 0 0 432000000 0 0>,
				      <0 0 0 0 0 0 600000000 0 0>;
			clock-cntl-level = "svs", "svs_l1", "turbo";
			src-clock-name = "ife_clk_src";
			clock-names-option = "ife_dsp_clk";
			clocks-option = <&camcc CAM_CC_IFE_1_DSP_CLK>;
			clock-rates-option = <600000000>;
			status = "okay";
		};

		cam_csid_lite: qcom,csid-lite@acc8000 {
			cell-index = <2>;
			compatible = "qcom,csid-lite170";
			reg-names = "csid-lite";
			reg = <0x0acc8000 0x1000>;
			reg-cam-base = <0xc8000>;
			interrupt-names = "csid-lite";
			interrupts = <GIC_SPI 473 IRQ_TYPE_EDGE_RISING>;
			power-domains = <&camcc TITAN_TOP_GDSC>;
			clock-names = "camera_ahb",
				      "camera_axi",
				      "soc_ahb_clk",
				      "cpas_ahb_clk",
				      "slow_ahb_clk_src",
				      "ife_csid_clk",
				      "ife_csid_clk_src",
				      "ife_cphy_rx_clk",
				      "cphy_rx_clk_src",
				      "ife_clk",
				      "ife_clk_src",
				      "camnoc_axi_clk";
			clocks = <&gcc GCC_CAMERA_AHB_CLK>,
				 <&gcc GCC_CAMERA_HF_AXI_CLK>,
				 <&camcc CAM_CC_SOC_AHB_CLK>,
				 <&camcc CAM_CC_CPAS_AHB_CLK>,
				 <&camcc CAM_CC_SLOW_AHB_CLK_SRC>,
				 <&camcc CAM_CC_IFE_LITE_CSID_CLK>,
				 <&camcc CAM_CC_IFE_LITE_CSID_CLK_SRC>,
				 <&camcc CAM_CC_IFE_LITE_CPHY_RX_CLK>,
				 <&camcc CAM_CC_CPHY_RX_CLK_SRC>,
				 <&camcc CAM_CC_IFE_LITE_CLK>,
				 <&camcc CAM_CC_IFE_LITE_CLK_SRC>,
				 <&camcc CAM_CC_CAMNOC_AXI_CLK>;
			clock-rates = <0 0 0 0 0 0 270000000 0 0 0 360000000 0>,
				      <0 0 0 0 0 0 360000000 0 0 0 432000000 0>,
				      <0 0 0 0 0 0 480000000 0 0 0 600000000 0>;
			clock-cntl-level = "svs", "svs_l1", "turbo";
			src-clock-name = "ife_csid_clk_src";
			status = "okay";
		};

		cam_vfe_lite: qcom,vfe-lite@acc4000 {
			cell-index = <2>;
			compatible = "qcom,vfe-lite170";
			reg-names = "ife-lite";
			reg = <0x0acc4000 0x4000>;
			reg-cam-base = <0xc4000>;
			interrupt-names = "ife-lite";
			interrupts = <GIC_SPI 472 IRQ_TYPE_EDGE_RISING>;
			power-domains = <&camcc TITAN_TOP_GDSC>;
			clock-names = "camera_ahb",
				      "camera_axi",
				      "soc_ahb_clk",
				      "cpas_ahb_clk",
				      "slow_ahb_clk_src",
				      "ife_clk",
				      "ife_clk_src",
				      "camnoc_axi_clk";
			clocks = <&gcc GCC_CAMERA_AHB_CLK>,
				 <&gcc GCC_CAMERA_HF_AXI_CLK>,
				 <&camcc CAM_CC_SOC_AHB_CLK>,
				 <&camcc CAM_CC_CPAS_AHB_CLK>,
				 <&camcc CAM_CC_SLOW_AHB_CLK_SRC>,
				 <&camcc CAM_CC_IFE_LITE_CLK>,
				 <&camcc CAM_CC_IFE_LITE_CLK_SRC>,
				 <&camcc CAM_CC_CAMNOC_AXI_CLK>;
			clock-rates = <0 0 0 0 0 0 360000000 0>,
				      <0 0 0 0 0 0 432000000 0>,
				      <0 0 0 0 0 0 600000000 0>;
			clock-cntl-level = "svs", "svs_l1", "turbo";
			src-clock-name = "ife_clk_src";
			status = "okay";
		};

		qcom,cam-jpeg {
			compatible = "qcom,cam-jpeg";
			compat-hw-name = "qcom,jpegenc",
					 "qcom,jpegdma";
			num-jpeg-enc = <1>;
			num-jpeg-dma = <1>;
			status = "okay";
		};

		cam_jpeg_enc: qcom,jpegenc@ac4e000 {
			cell-index = <0>;
			compatible = "qcom,cam_jpeg_enc";
			reg-names = "jpege_hw";
			reg = <0x0ac4e000 0x4000>;
			reg-cam-base = <0x4e000>;
			interrupt-names = "jpeg";
			interrupts = <GIC_SPI 474 IRQ_TYPE_EDGE_RISING>;
			power-domains = <&camcc TITAN_TOP_GDSC>;
			clock-names = "camera_ahb",
				      "camera_axi",
				      "soc_ahb_clk",
				      "cpas_ahb_clk",
				      "camnoc_axi_clk",
				      "jpegenc_clk_src",
				      "jpegenc_clk";
			clocks = <&gcc GCC_CAMERA_AHB_CLK>,
				 <&gcc GCC_CAMERA_HF_AXI_CLK>,
				 <&camcc CAM_CC_SOC_AHB_CLK>,
				 <&camcc CAM_CC_CPAS_AHB_CLK>,
				 <&camcc CAM_CC_CAMNOC_AXI_CLK>,
				 <&camcc CAM_CC_JPEG_CLK_SRC>,
				 <&camcc CAM_CC_JPEG_CLK>;
			clock-rates = <0 0 0 0 0 600000000 0>;
			src-clock-name = "jpegenc_clk_src";
			clock-cntl-level = "turbo";
			status = "okay";
		};

		cam_jpeg_dma: qcom,jpegdma@ac52000 {
			cell-index = <0>;
			compatible = "qcom,cam_jpeg_dma";
			reg-names = "jpegdma_hw";
			reg = <0x0ac52000 0x4000>;
			reg-cam-base = <0x52000>;
			interrupt-names = "jpegdma";
			interrupts = <GIC_SPI 475 IRQ_TYPE_EDGE_RISING>;
			power-domains = <&camcc TITAN_TOP_GDSC>;
			clock-names = "camera_ahb",
				      "camera_axi",
				      "soc_ahb_clk",
				      "cpas_ahb_clk",
				      "camnoc_axi_clk",
				      "jpegdma_clk_src",
				      "jpegdma_clk";
			clocks = <&gcc GCC_CAMERA_AHB_CLK>,
				 <&gcc GCC_CAMERA_HF_AXI_CLK>,
				 <&camcc CAM_CC_SOC_AHB_CLK>,
				 <&camcc CAM_CC_CPAS_AHB_CLK>,
				 <&camcc CAM_CC_CAMNOC_AXI_CLK>,
				 <&camcc CAM_CC_JPEG_CLK_SRC>,
				 <&camcc CAM_CC_JPEG_CLK>;
			clock-rates = <0 0 0 0 0 600000000 0>;
			src-clock-name = "jpegdma_clk_src";
			clock-cntl-level = "turbo";
			status = "okay";
		};

		qcom,cam-lrme {
			compatible = "qcom,cam-lrme";
			arch-compat = "lrme";
			status = "okay";
		};

		cam_lrme: qcom,lrme@ac6b000 {
			cell-index = <0>;
			compatible = "qcom,lrme";
			reg-names = "lrme";
			reg = <0x0ac6b000 0x1000>;
			reg-cam-base = <0x6b000>;
			interrupt-names = "lrme";
			interrupts = <GIC_SPI 476 IRQ_TYPE_EDGE_RISING>;
			power-domains = <&camcc TITAN_TOP_GDSC>;
			clock-names = "camera_ahb",
				      "camera_axi",
				      "soc_ahb_clk",
				      "cpas_ahb_clk",
				      "camnoc_axi_clk",
				      "lrme_clk_src",
				      "lrme_clk";
			clocks = <&gcc GCC_CAMERA_AHB_CLK>,
				 <&gcc GCC_CAMERA_HF_AXI_CLK>,
				 <&camcc CAM_CC_SOC_AHB_CLK>,
				 <&camcc CAM_CC_CPAS_AHB_CLK>,
				 <&camcc CAM_CC_CAMNOC_AXI_CLK>,
				 <&camcc CAM_CC_LRME_CLK_SRC>,
				 <&camcc CAM_CC_LRME_CLK>;
			clock-rates = <0 0 0 0 0 200000000 200000000>,
				      <0 0 0 0 0 216000000 216000000>,
				      <0 0 0 0 0 300000000 300000000>,
				      <0 0 0 0 0 404000000 404000000>,
				      <0 0 0 0 0 404000000 404000000>,
				      <0 0 0 0 0 404000000 404000000>;
			clock-cntl-level = "lowsvs", "svs", "svs_l1",
					   "nominal", "nominal_l1", "turbo";
			src-clock-name = "lrme_clk_src";
			status = "okay";
		};

		/*
		 * Must be LAST inside camera-kt so all platform child devices
		 * are already populated when cam_req_mgr_probe() calls
		 * camera_component_match_add_drivers().
		 */
		qcom,cam-req-mgr {
			compatible = "qcom,cam-req-mgr";
			status = "okay";
		};
	};
};
